# NANO112AN_v1 register map
File version: 1.0
Registers are 32-bit, read-write, reset 0x0 unless marked. A register's access mark holds for its fields unless they carry their own. Offsets are from the block's base; [hi:lo] are bit positions; {n}, {i} and the like mark numbered series; 'fields as' and 'values as' point back to an identical list.

## ADC — ADC Register Map
Base 0x400E0000
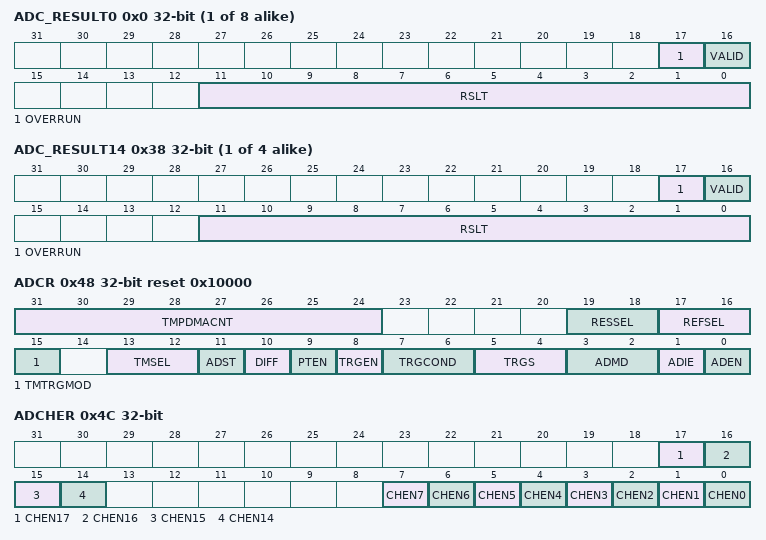
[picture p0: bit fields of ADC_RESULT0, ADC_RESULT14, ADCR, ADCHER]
{0x0+4i} ADC_RESULT{i} ro (i=0..7) — A/D Data Register {i}
  [17] OVERRUN — Over Run Flag. When VALID is high and ADC converts finish, this field will set to high.
  [16] VALID — Data Valid Flag. After ADC converts finish, this field will set to high. This field will clear when this register be read.
  [11:0] RSLT — A/D Conversion Result. This field contains 12 bits conversion results.
{0x0+4i} ADC_RESULT{i} ro (i=14..17) — A/D Data Register {i}
  fields as ADC_RESULT0
0x48 ADCR reset 0x10000 — A/D Control Register
  [31:24] TMPDMACNT — PDMA Count. When each timer event occur PDMA will transfer TMPDMACNT +1 ADC result in the amount of this register setting. Note: The total amount of PDMA transferring data should be set in PDMA byte count register. When PDMA finish is set, ADC will not be enabled and start transfer even though the timer event occurred
  [19:18] RESSEL — Resolution Selection
    0=6 bits. ADC result will put at RSLT[5:0] (ADC_RESULTx[5:0]),; 1=8 bits. ADC result will put at RSLT[7:0] (ADC_RESULTx[7:0]); 2=10 bits. ADC result will put at RSLT[9:0] (ADC_RESULTx[9:0]); 3=12 bits. ADC result will put at RSLT (ADC_RESULTx[11:0])
  [17:16] REFSEL — Reference Voltage Source Selection
    0=Select AVDD as reference voltage; 1=Select Int_VREF as reference voltage; 2=Select VREF as reference voltage
  [15] TMTRGMOD — Timer Event Trigger ADC Conversion setting TMSEL to select timer event from timer0~3
    0=This function Disabled; 1=ADC Enabled by TiMER OUt event
  [13:12] TMSEL — Select A/D Enable Time-out Source
    {v}=TMR{v} (v=0..3)
  [11] ADST — A/D Conversion Start. ADST bit can be set to 1 from three sources: software write, external pin STADC and PWM trigger. ADST is cleared to 0 by hardware automatically at the end of single mode and single-cycle scan mode on specified channels. In continuous scan mode, A/D conversion is continuously performed sequentially unless software writes 0 to this bit or chip reset. Note: After ADC conversion done, SW needs to wait at least one ADC clock before to set this bit high again.
    0=Conversion stopped and A/D converter enter idle state; 1=Conversion starts
  [10] DIFF — Differential Mode Selection. Note: Calibration should calibrated each time when switching between single-ended and differential mode
    0=ADC is operated in single-ended mode; 1=ADC is operated in differential mode
  [9] PTEN — PDMA Transfer Enable Control
    0=PDMA data transfer Disabled; 1=PDMA data transfer in ADC_RESULT 0~17 Enabled
  [8] TRGEN — External Trigger Enable Control. Enable or disable triggering of A/D conversion by external STADC pin.
    0=Disabled,; 1=Enabled,
  [7:6] TRGCOND — External Trigger Condition. These two bits decide external pin STADC trigger event is level or edge. The signal must be kept at stable state at least 8 PCLKs for level trigger and 4 PCLKs at high and low state.
    0=Low level; 1=High level; 2=Falling edge; 3=Rising edge
  [5:4] TRGS — Hardware Trigger Source. Software should disable TRGE and ADST before change TRGS. In hardware trigger mode, the ADST bit is set by the external trigger from STADC or PWM trigger, However software has the highest priority to set or cleared ADST bit at any time.
    0=A/D conversion is started by external STADC pin; 3=PWM trigger
  [3:2] ADMD — A/D Converter Operation Mode
    0=Single conversion; 2=Single-cycle scan; 3=Continuous scan
  [1] ADIE — A/D Interrupt Enable Control. A/D conversion end interrupt request is generated if ADIE bit is set to 1.
    0=A/D interrupt function Disabled; 1=A/D interrupt function Enabled
  [0] ADEN — A/D Converter Enable Control. Before starting A/D conversion, this bit should be set to 1. Clear it to 0 to disable A/D converter analog circuit power consumption.
    0=Disabled; 1=Enabled
0x4C ADCHER — A/D Channel Enable Register
  [all] fields
    0=Disabled; 1=Enabled
  [17] CHEN17 — Analog Input Channel 17 Enable Control (Convert AVSS)
  [16] CHEN16 — Analog Input Channel 16 Enable Control (Convert AVDD)
  [15] CHEN15 — Analog Input Channel 15 Enable Control (Convert Int_VREF)
  [14] CHEN14 — Analog Input Channel 14 Enable Control (Convert VTEMP)
  [7] CHEN7 — Analog Input Channel 7 Enable Control (Convert Input Voltage From PA.7 )
  [6] CHEN6 — Analog Input Channel 6 Enable Control (Convert Input Voltage From PA.6 )
  [5] CHEN5 — Analog Input Channel 5 Enable Control (Convert Input Voltage From PA.5 )
  [4] CHEN4 — Analog Input Channel 4 Enable Control (Convert Input Voltage From PA.4 )
  [3] CHEN3 — Analog Input Channel 3 Enable Control (Convert Input Voltage From PA.3 )
  [2] CHEN2 — Analog Input Channel 2 Enable Control (Convert Input Voltage From PA.2 )
  [1] CHEN1 — Analog Input Channel 1 Enable Control (Convert Input Voltage From PA.1 )
  [0] CHEN0 — Analog Input Channel 0 Enable Control (Convert Input Voltage From PA.0 ). If more than one channel in single mode is enabled by software, the least channel is converted and other enabled channels will be ignored.
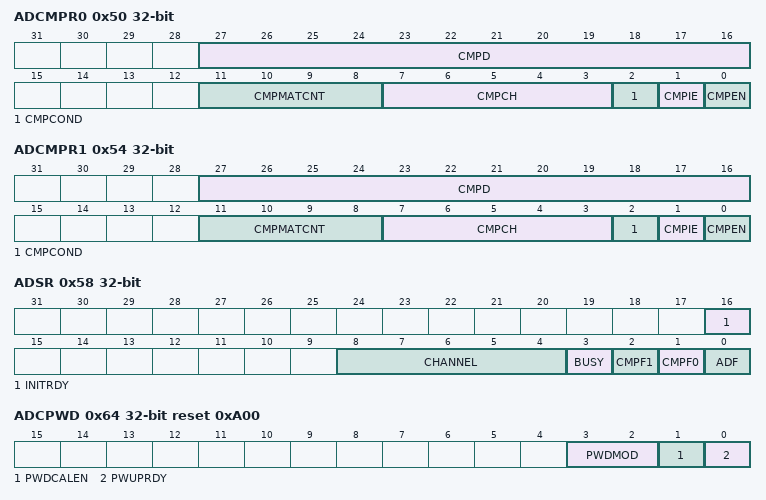
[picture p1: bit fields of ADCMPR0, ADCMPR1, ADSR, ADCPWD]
0x50 ADCMPR0 — A/D Compare Register 0
  [27:16] CMPD — Comparison Data. The 12 bits data is used to compare with conversion result of specified channel. Software can use it to monitor the external analog input pin voltage variation in scan mode without imposing a load on software.
  [11:8] CMPMATCNT — Compare Match Count. When the specified A/D channel analog conversion result matches the compare condition defined by CMPCOND[2], the internal match counter will increase 1. When the internal counter reaches the value to (CMPMATCNT +1), the CMPF bit will be set.
  [7:3] CMPCH — Compare Channel Selection. Set this field to select which channel's result to be compared. Note: Valid setting of this field is channel 0~17, but channel 8~14 are reserved.
  [2] CMPCOND — Compare Condition. Note: When the internal counter reaches the value to (CMPMATCNT +1), the CMPF bit will be set.
    0=Set the compare condition as that when a 12-bit A/D conversion result is less than the 12-bit CMPD (ADCMPRx[27:16]), the internal match counter will increase one; 1=Set the compare condition as that when a 12-bit A/D conversion result is greater or equal to the 12-bit CMPD (ADCMPRx[27:16]), the internal match counter will increase by one
  [1] CMPIE — Compare Interrupt Enable Control. If the compare function is enabled and the compare condition matches the setting of CMPCOND and CMPMATCNT, CMPF bit will be asserted, in the meanwhile, if CMPIE is set to 1, a compare interrupt request is generated.
    0=Compare function interrupt Disabled; 1=Compare function interrupt Enabled
  [0] CMPEN — Compare Enable Control. Set this bit to 1 to enable compare CMPD[11:0] with specified channel conversion result when converted data is loaded into ADC_RESULTx register. When this bit is set to 1, and CMPMATCNT is 0, the CMPF will be set once the match is hit.
    0=Compare Disabled; 1=Compare Enabled
0x54 ADCMPR1 — A/D Compare Register 1
  fields as ADCMPR0
0x58 ADSR — A/D Status Register
  [16] INITRDY — ADC Power-up Sequence Completed. Note: This bit will be set after system reset occurred and automatically cleared by power-up event.
    0=ADC not powered up after system reset; 1=ADC has been powered up since the last system reset
  [8:4] CHANNEL ro — Current Conversion Channel (Read Only)
  [3] BUSY ro — BUSY/IDLE (Read Only)
    0=A/D converter is in idle state; 1=A/D converter is busy at conversion
  [2] CMPF1 — Compare Flag. When the selected channel A/D conversion result meets setting condition in ADCMPR1 then this bit is set to 1. And it is cleared by writing 1 to self. This flag can be cleared by writing 1 to it. Note: When this flag is set, the matching counter will be reset to 0,and continue to count when user writes 1 to clear CMPF1.
    0=Conversion result in ADC_RESULTx does not meet ADCMPR1 setting; 1=Conversion result in ADC_RESULTx meets ADCMPR1 setting
  [1] CMPF0 — Compare Flag. When the selected channel A/D conversion result meets setting condition in ADCMPR0 then this bit is set to 1. And it is cleared by writing 1 to self. This flag can be cleared by writing 1 to it. Note: When this flag is set, the matching counter will be reset to 0,and continue to count when user write 1 to clear CMPF0
    0=Conversion result in ADC_RESULTx does not meet ADCMPR0setting; 1=Conversion result in ADC_RESULTx meets ADCMPR0setting
  [0] ADF — A/D Conversion End Flag. A status flag that indicates the end of A/D conversion. ADF is set to 1 at these two conditions: When A/D conversion ends in single mode. When A/D conversion ends on all specified channels in scan mode. This flag can be cleared by writing 1 to it.
0x60 ADPDMA ro — A/D PDMA Current Transfer Data Register
  [11:0] AD_PDMA — ADC PDMA Current Transfer Data (Read Only). When PDMA transferring, reading these bits can monitor the current PDMA transfer data.
0x64 ADCPWD reset 0xA00 — ADC Power Management Register
  [3:2] PWDMOD — ADC Power-down Mode. Set this bit fields to select ADC Power-down mode when system power-down. Note1: Different PWDMOD has different power down/up sequence, in order to avoid ADC powering up with wrong sequence; user must keep PWMOD consistent each time in power down and power up. Note2: While the ADC is power up from Power-down mode without calibration, the PWDCALEN(ADCPWD[1]) is set to 0. (The calibration value will be reset)
    1=ADC Power-down mode; 2=ADC Standby mode
  [1] PWDCALEN — Power Up Calibration Function Enable Control. Note: This bit work together with CALSEL (ADCCALCTL[3]), see the following {PWDCALEN,CALFBSEL} Description: PWDCALEN is 0 and CALFBSEL is 0: No need to calibrate. PWDCALEN is 0 and CALFBSEL is 1: No need to calibrate. PWDCALEN is 1 and CALFBSEL is 0: Load calibration word when power up. PWDCALEN is 1 and CALFBSEL is 1: Calibrate when power up.
    0=Power up without calibration; 1=Power up with calibration
  [0] PWUPRDY — ADC Power-up Sequence Completed and Ready for Conversion
    0=ADC is not ready for conversion may be in power down state or in the progress of power up; 1=ADC is ready for conversion
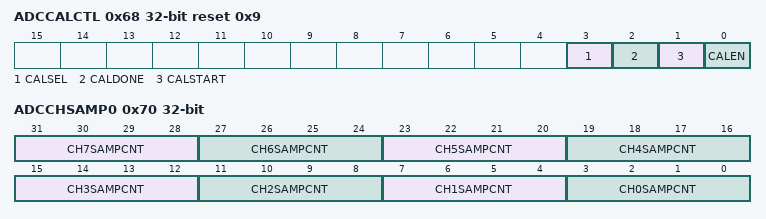
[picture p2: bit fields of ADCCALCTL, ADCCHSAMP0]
0x68 ADCCALCTL reset 0x9 — ADC Calibration Control Register
  [3] CALSEL — Select Calibration Functional Block
    0=Load calibration functional block; 1=Calibration functional block
  [2] CALDONE — Calibrate Functional Block Complete
    0=Not yet; 1=Selected functional block complete
  [1] CALSTART — Calibration Functional Block Start
    0=Stops calibration functional block; 1=Starts calibration functional block
  [0] CALEN — Calibration Function Enable Control. Enable this bit to turn on the calibration function block.
    0=(BYPASSCAL); 1=Enabled
0x6C ADCCALWORD reset not defined — A/D Calibration Load Word Register
  [6:0] CALWORD — Calibration Word Bits. Write to this register with the previous calibration word before load calibration action. Read this register after calibration done. Note: The calibration block contains two parts "CALIBRATION" and "LOAD CALIBRATION"; if the calibration block configure as "CALIBRATION"; then this register represent the result of calibration when calibration is completed; if configure as "LOAD CALIBRATION" ; configure this register before loading calibration action, after loading calibration complete, the laoded calibration word will apply to the ADC; while in loading calibration function the loaded value will not be equal to the original CALWORD until calibration is done.
0x70 ADCCHSAMP0 — ADC Channel Sampling Time Counter Register Group 0
  [4n+3:4n] CH{n}SAMPCNT (n=1..7) — Channel {n} Sampling Counter. The same as Channel 0 sampling counter table.
  [3:0] CH0SAMPCNT — Channel 0 Sampling Counter. CH0SAMPCNT ADC Clock
    0=0; 1=1; 2=2; 3=4; 4=8; 5=16; 6=32; 7=64; 8=128; 9=256; 10=512; {v}=1024 (v=11..15)
0x74 ADCCHSAMP1 — ADC Channel Sampling Time Counter Register Group 1
  [19:16] INTCHSAMPCNT — Internal Channel (VTEMP, AVDD, AVSS, Int_VREF) Sampling Counter. The same as Channel 0 sampling counter table.
